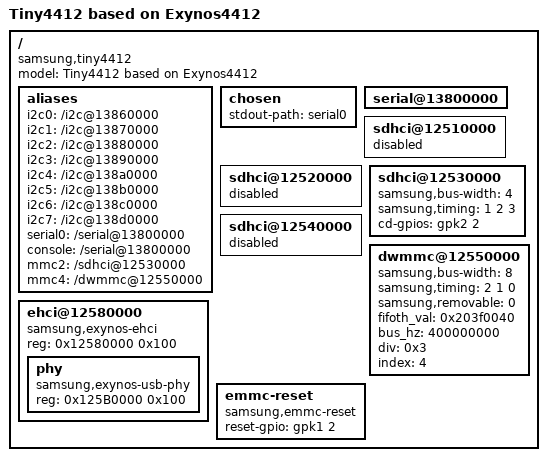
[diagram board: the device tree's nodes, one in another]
/*
 *			2017
 * 	Modified by AP0904225 <ap0904225@qq.com>  on the basis of odroid board
 *
 * Configuration settings for the FriendlyARM TINY4412 (EXYNOS4412) board.
 *     FriendlyARM Tiny4412 SDK board hardware version:
 *           core board   :  Tiny4412-1412
 *           bottom board :  Tiny4412/Super4412SDK 1506
 *
 * SPDX-License-Identifier:	GPL-2.0+
 */

/dts-v1/;
#include "exynos4412.dtsi"

/ {
	model = "Tiny4412 based on Exynos4412";
	compatible = "samsung,tiny4412", "samsung,exynos4412";

	aliases {
		i2c0 = "/i2c@13860000";
		i2c1 = "/i2c@13870000";
		i2c2 = "/i2c@13880000";
		i2c3 = "/i2c@13890000";
		i2c4 = "/i2c@138a0000";
		i2c5 = "/i2c@138b0000";
		i2c6 = "/i2c@138c0000";
		i2c7 = "/i2c@138d0000";
		serial0 = "/serial@13800000";
		console = "/serial@13800000";
		mmc2 = "/sdhci@12530000";
		mmc4 = "/dwmmc@12550000";
	};
	chosen {
       stdout-path = "serial0";
    };

	serial@13800000 {
		status = "okay";
	};

	sdhci@12510000 {
		status = "disabled";
	};

	sdhci@12520000 {
		status = "disabled";
	};

	sdhci@12530000 {
		samsung,bus-width = <4>;
		samsung,timing = <1 2 3>;
		cd-gpios = <&gpk2 2 0>;
	};

	sdhci@12540000 {
		status = "disabled";
	};

	dwmmc@12550000 {
		samsung,bus-width = <8>;
		samsung,timing = <2 1 0>;
		samsung,removable = <0>;
		fifoth_val = <0x203f0040>;
		bus_hz = <400000000>;
		div = <0x3>;
		index = <4>;
	};

	ehci@12580000 {
		compatible = "samsung,exynos-ehci";
		reg = <0x12580000 0x100>;
		#address-cells = <1>;
		#size-cells = <1>;
		phy {
			compatible = "samsung,exynos-usb-phy";
			reg = <0x125B0000 0x100>;
		};
	};

	emmc-reset {
		compatible = "samsung,emmc-reset";
		reset-gpio = <&gpk1 2 0>;
	};
};
